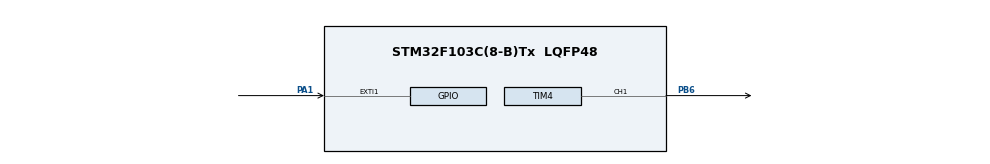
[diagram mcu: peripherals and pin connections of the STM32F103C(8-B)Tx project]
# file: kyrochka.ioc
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Mcu.Family=STM32F1
Mcu.Name=STM32F103C(8-B)Tx
Mcu.Package=LQFP48
NVIC.EXTI1_IRQn=true\:0\:0\:false\:false\:true
NVIC.PriorityGroup=NVIC_PRIORITYGROUP_4
NVIC.TIM3_IRQn=true\:0\:0\:false\:false\:true
PA1.GPIO_ModeDefaultEXTI=GPIO_MODE_IT_RISING
PA1.GPIO_PuPd=GPIO_NOPULL
PA1.Signal=GPXTI1
PB6.GPIO_ModeDefaultPP=GPIO_MODE_AF_PP
PB6.GPIO_Speed=GPIO_SPEED_FREQ_LOW
PB6.Signal=S_TIM4_CH1
PD0-OSC_IN.Mode=HSE-External-Oscillator
PD0-OSC_IN.Signal=RCC_OSC_IN
PD1-OSC_OUT.Mode=HSE-External-Oscillator
PD1-OSC_OUT.Signal=RCC_OSC_OUT
ProjectManager.HeapSize=0x200
ProjectManager.StackSize=0x400
ProjectManager.TargetToolchain=MDK-ARM V5
RCC.APB1Freq_Value=8000000
RCC.APB2Freq_Value=8000000
SH.S_TIM4_CH1.0=TIM4_CH1,PWM Generation1 CH1
TIM3.Channel-Output\ Compare1\ No\ Output=TIM_CHANNEL_1
TIM3.Period=1999
TIM3.Prescaler=7999
TIM4.Channel-PWM\ Generation1\ CH1=TIM_CHANNEL_1
TIM4.Period=99
VP_SYS_VS_ND.Mode=No_Debug
VP_TIM3_VS_ClockSourceINT.Mode=Internal
VP_TIM3_VS_no_output1.Mode=Output Compare1 No Output
VP_TIM4_VS_ClockSourceINT.Mode=Internal
board=kyrochka

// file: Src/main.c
/**
  ******************************************************************************
  * File Name          : main.c
  * Description        : Main program body
  ******************************************************************************
  ** This notice applies to any and all portions of this file
  * that are not between comment pairs USER CODE BEGIN and
  * USER CODE END. Other portions of this file, whether
  * inserted by the user or by software development tools
  * are owned by their respective copyright owners.
  *
  * COPYRIGHT(c) 2018 STMicroelectronics
  *
  * Redistribution and use in source and binary forms, with or without modification,
  * are permitted provided that the following conditions are met:
  *   1. Redistributions of source code must retain the above copyright notice,
  *      this list of conditions and the following disclaimer.
  *   2. Redistributions in binary form must reproduce the above copyright notice,
  *      this list of conditions and the following disclaimer in the documentation
  *      and/or other materials provided with the distribution.
  *   3. Neither the name of STMicroelectronics nor the names of its contributors
  *      may be used to endorse or promote products derived from this software
  *      without specific prior written permission.
  *
  * THIS SOFTWARE IS PROVIDED BY THE COPYRIGHT HOLDERS AND CONTRIBUTORS "AS IS"
  * AND ANY EXPRESS OR IMPLIED WARRANTIES, INCLUDING, BUT NOT LIMITED TO, THE
  * IMPLIED WARRANTIES OF MERCHANTABILITY AND FITNESS FOR A PARTICULAR PURPOSE ARE
  * DISCLAIMED. IN NO EVENT SHALL THE COPYRIGHT HOLDER OR CONTRIBUTORS BE LIABLE
  * FOR ANY DIRECT, INDIRECT, INCIDENTAL, SPECIAL, EXEMPLARY, OR CONSEQUENTIAL
  * DAMAGES (INCLUDING, BUT NOT LIMITED TO, PROCUREMENT OF SUBSTITUTE GOODS OR
  * SERVICES; LOSS OF USE, DATA, OR PROFITS; OR BUSINESS INTERRUPTION) HOWEVER
  * CAUSED AND ON ANY THEORY OF LIABILITY, WHETHER IN CONTRACT, STRICT LIABILITY,
  * OR TORT (INCLUDING NEGLIGENCE OR OTHERWISE) ARISING IN ANY WAY OUT OF THE USE
  * OF THIS SOFTWARE, EVEN IF ADVISED OF THE POSSIBILITY OF SUCH DAMAGE.
  *
  ******************************************************************************
  */
#include "main.h"
#include "stm32f1xx_hal.h"

TIM_HandleTypeDef htim3;
TIM_HandleTypeDef htim4;

/* USER CODE BEGIN PV */
/* Private variables ---------------------------------------------------------*/

/* USER CODE END PV */

void SystemClock_Config(void);
static void MX_GPIO_Init(void);
static void MX_TIM4_Init(void);
static void MX_TIM3_Init(void);

void HAL_TIM_MspPostInit(TIM_HandleTypeDef *htim);

/* USER CODE BEGIN PFP */
/* Private function prototypes -----------------------------------------------*/

/* USER CODE END PFP */

/* USER CODE BEGIN 0 */
uint32_t i;
/* USER CODE END 0 */

int main(void)
{

  /* USER CODE BEGIN 1 */
	/*int a = 0;
	while(a!=count){
		a++;
		HAL_GPIO_WritePin();
		HAL_Delay(500);

	}*/
  /* USER CODE END 1 */

  /* MCU Configuration----------------------------------------------------------*/

  /* Reset of all peripherals, Initializes the Flash interface and the Systick. */
  HAL_Init();

  /* Configure the system clock */
  SystemClock_Config();

  /* Initialize all configured peripherals */
  MX_GPIO_Init();
  MX_TIM4_Init();
  MX_TIM3_Init();

  /* USER CODE BEGIN 2 */
	HAL_TIM_PWM_Start(&htim4,TIM_CHANNEL_1);
	HAL_TIM_Base_Start_IT( &htim3);

  extern int shine;
  /* USER CODE END 2 */

  /* Infinite loop */
  while (1)
  {

  /* USER CODE BEGIN 3 */
	//	__HAL_TIM_SET_COMPARE(&htim4, TIM_CHANNEL_1, 99);
			//__HAL_TIM_SET_COMPARE(&htim4, TIM_CHANNEL_1, shine);
	HAL_Delay(1);
		//__HAL_TIM_SET_COMPARE(&htim4, TIM_CHANNEL_1, 50);
		 //HAL_Delay(2000);
		//__HAL_TIM_SET_COMPARE(&htim4, TIM_CHANNEL_1, 100);
		 //HAL_Delay(2000);
		//__HAL_TIM_SET_COMPARE(&htim4, TIM_CHANNEL_1, 0);
		//__HAL_TIM_SET_COMPARE(&htim4, TIM_CHANNEL_1, k);
			//HAL_TIM_PWM_ConfigChannel(&htim4, TIM_CHANNEL_1, i);

	}
  /* USER CODE END 3 */

}

/** System Clock Configuration
*/
void SystemClock_Config(void)
{

  RCC_OscInitTypeDef RCC_OscInitStruct;
  RCC_ClkInitTypeDef RCC_ClkInitStruct;

    /**Initializes the CPU, AHB and APB busses clocks
    */
  RCC_OscInitStruct.OscillatorType = RCC_OSCILLATORTYPE_HSI;
  RCC_OscInitStruct.HSIState = RCC_HSI_ON;
  RCC_OscInitStruct.HSICalibrationValue = 16;
  RCC_OscInitStruct.PLL.PLLState = RCC_PLL_NONE;
  if (HAL_RCC_OscConfig(&RCC_OscInitStruct) != HAL_OK)
  {
    _Error_Handler(__FILE__, __LINE__);
  }

    /**Initializes the CPU, AHB and APB busses clocks
    */
  RCC_ClkInitStruct.ClockType = RCC_CLOCKTYPE_HCLK|RCC_CLOCKTYPE_SYSCLK
                              |RCC_CLOCKTYPE_PCLK1|RCC_CLOCKTYPE_PCLK2;
  RCC_ClkInitStruct.SYSCLKSource = RCC_SYSCLKSOURCE_HSI;
  RCC_ClkInitStruct.AHBCLKDivider = RCC_SYSCLK_DIV1;
  RCC_ClkInitStruct.APB1CLKDivider = RCC_HCLK_DIV1;
  RCC_ClkInitStruct.APB2CLKDivider = RCC_HCLK_DIV1;

  if (HAL_RCC_ClockConfig(&RCC_ClkInitStruct, FLASH_LATENCY_0) != HAL_OK)
  {
    _Error_Handler(__FILE__, __LINE__);
  }

    /**Configure the Systick interrupt time
    */
  HAL_SYSTICK_Config(HAL_RCC_GetHCLKFreq()/1000);

    /**Configure the Systick
    */
  HAL_SYSTICK_CLKSourceConfig(SYSTICK_CLKSOURCE_HCLK);

  /* SysTick_IRQn interrupt configuration */
  HAL_NVIC_SetPriority(SysTick_IRQn, 0, 0);
}

/* TIM3 init function */
static void MX_TIM3_Init(void)
{

  TIM_ClockConfigTypeDef sClockSourceConfig;
  TIM_MasterConfigTypeDef sMasterConfig;
  TIM_OC_InitTypeDef sConfigOC;

  htim3.Instance = TIM3;
  htim3.Init.Prescaler = 7999;
  htim3.Init.CounterMode = TIM_COUNTERMODE_UP;
  htim3.Init.Period = 1999;
  htim3.Init.ClockDivision = TIM_CLOCKDIVISION_DIV1;
  htim3.Init.AutoReloadPreload = TIM_AUTORELOAD_PRELOAD_DISABLE;
  if (HAL_TIM_Base_Init(&htim3) != HAL_OK)
  {
    _Error_Handler(__FILE__, __LINE__);
  }

  sClockSourceConfig.ClockSource = TIM_CLOCKSOURCE_INTERNAL;
  if (HAL_TIM_ConfigClockSource(&htim3, &sClockSourceConfig) != HAL_OK)
  {
    _Error_Handler(__FILE__, __LINE__);
  }

  if (HAL_TIM_OC_Init(&htim3) != HAL_OK)
  {
    _Error_Handler(__FILE__, __LINE__);
  }

  sMasterConfig.MasterOutputTrigger = TIM_TRGO_RESET;
  sMasterConfig.MasterSlaveMode = TIM_MASTERSLAVEMODE_DISABLE;
  if (HAL_TIMEx_MasterConfigSynchronization(&htim3, &sMasterConfig) != HAL_OK)
  {
    _Error_Handler(__FILE__, __LINE__);
  }

  sConfigOC.OCMode = TIM_OCMODE_TIMING;
  sConfigOC.Pulse = 0;
  sConfigOC.OCPolarity = TIM_OCPOLARITY_HIGH;
  sConfigOC.OCFastMode = TIM_OCFAST_DISABLE;
  if (HAL_TIM_OC_ConfigChannel(&htim3, &sConfigOC, TIM_CHANNEL_1) != HAL_OK)
  {
    _Error_Handler(__FILE__, __LINE__);
  }

}

/* TIM4 init function */
static void MX_TIM4_Init(void)
{

  TIM_ClockConfigTypeDef sClockSourceConfig;
  TIM_MasterConfigTypeDef sMasterConfig;
  TIM_OC_InitTypeDef sConfigOC;

  htim4.Instance = TIM4;
  htim4.Init.Prescaler = 0;
  htim4.Init.CounterMode = TIM_COUNTERMODE_UP;
  htim4.Init.Period = 99;
  htim4.Init.ClockDivision = TIM_CLOCKDIVISION_DIV1;
  htim4.Init.AutoReloadPreload = TIM_AUTORELOAD_PRELOAD_DISABLE;
  if (HAL_TIM_Base_Init(&htim4) != HAL_OK)
  {
    _Error_Handler(__FILE__, __LINE__);
  }

  sClockSourceConfig.ClockSource = TIM_CLOCKSOURCE_INTERNAL;
  if (HAL_TIM_ConfigClockSource(&htim4, &sClockSourceConfig) != HAL_OK)
  {
    _Error_Handler(__FILE__, __LINE__);
  }

  if (HAL_TIM_PWM_Init(&htim4) != HAL_OK)
  {
    _Error_Handler(__FILE__, __LINE__);
  }

  sMasterConfig.MasterOutputTrigger = TIM_TRGO_RESET;
  sMasterConfig.MasterSlaveMode = TIM_MASTERSLAVEMODE_DISABLE;
  if (HAL_TIMEx_MasterConfigSynchronization(&htim4, &sMasterConfig) != HAL_OK)
  {
    _Error_Handler(__FILE__, __LINE__);
  }

  sConfigOC.OCMode = TIM_OCMODE_PWM1;
  sConfigOC.Pulse = 0;
  sConfigOC.OCPolarity = TIM_OCPOLARITY_HIGH;
  sConfigOC.OCFastMode = TIM_OCFAST_DISABLE;
  if (HAL_TIM_PWM_ConfigChannel(&htim4, &sConfigOC, TIM_CHANNEL_1) != HAL_OK)
  {
    _Error_Handler(__FILE__, __LINE__);
  }

  HAL_TIM_MspPostInit(&htim4);

}

/** Configure pins as
        * Analog
        * Input
        * Output
        * EVENT_OUT
        * EXTI
*/
static void MX_GPIO_Init(void)
{

  GPIO_InitTypeDef GPIO_InitStruct;

  /* GPIO Ports Clock Enable */
  __HAL_RCC_GPIOD_CLK_ENABLE();
  __HAL_RCC_GPIOA_CLK_ENABLE();
  __HAL_RCC_GPIOB_CLK_ENABLE();

  /*Configure GPIO pin : PA1 */
  GPIO_InitStruct.Pin = GPIO_PIN_1;
  GPIO_InitStruct.Mode = GPIO_MODE_IT_RISING;
  GPIO_InitStruct.Pull = GPIO_NOPULL;
  HAL_GPIO_Init(GPIOA, &GPIO_InitStruct);

  /* EXTI interrupt init*/
  HAL_NVIC_SetPriority(EXTI1_IRQn, 0, 0);
  HAL_NVIC_EnableIRQ(EXTI1_IRQn);

}

void _Error_Handler(char * file, int line)
{
  while(1)
  {
  }
}

/************************ (C) COPYRIGHT STMicroelectronics *****END OF FILE****/
